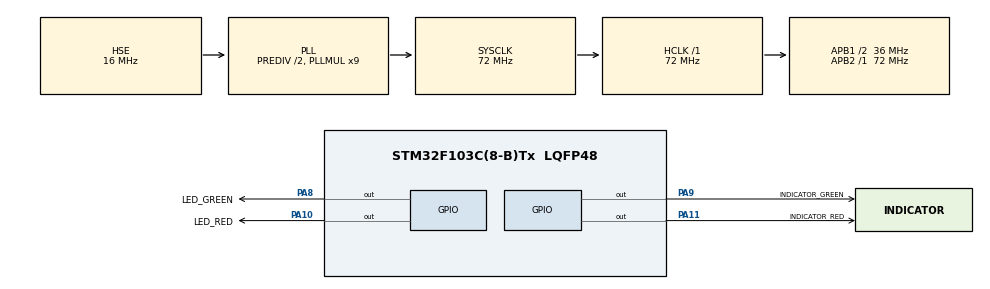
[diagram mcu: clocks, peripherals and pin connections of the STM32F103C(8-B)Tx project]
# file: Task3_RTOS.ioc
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FREERTOS.Tasks01=defaultTask,24,128,StartDefaultTask,Default,NULL,Dynamic,NULL,NULL;LedGreenTask,24,128,LedGreen,Default,NULL,Dynamic,NULL,NULL;LedRedTask,40,128,LedRed,Default,NULL,Dynamic,NULL,NULL
FREERTOS.configUSE_NEWLIB_REENTRANT=1
Mcu.Family=STM32F1
Mcu.Name=STM32F103C(8-B)Tx
Mcu.Package=LQFP48
NVIC.PriorityGroup=NVIC_PRIORITYGROUP_4
NVIC.TIM4_IRQn=true\:15\:0\:false\:false\:true\:false\:false\:true\:true
NVIC.TimeBase=TIM4_IRQn
NVIC.TimeBaseIP=TIM4
PA10.GPIO_Label=LED_RED
PA10.Signal=GPIO_Output
PA11.GPIO_Label=INDICATOR_RED
PA11.Signal=GPIO_Output
PA13.Mode=Serial_Wire
PA13.Signal=SYS_JTMS-SWDIO
PA14.Mode=Serial_Wire
PA14.Signal=SYS_JTCK-SWCLK
PA8.GPIO_Label=LED_GREEN
PA8.Signal=GPIO_Output
PA9.GPIO_Label=INDICATOR_GREEN
PA9.Signal=GPIO_Output
PD0-OSC_IN.Mode=HSE-External-Oscillator
PD0-OSC_IN.Signal=RCC_OSC_IN
PD1-OSC_OUT.Mode=HSE-External-Oscillator
PD1-OSC_OUT.Signal=RCC_OSC_OUT
ProjectManager.HeapSize=0x200
ProjectManager.StackSize=0x400
ProjectManager.TargetToolchain=STM32CubeIDE
RCC.AHBFreq_Value=72000000
RCC.APB1CLKDivider=RCC_HCLK_DIV2
RCC.APB1Freq_Value=36000000
RCC.APB1TimFreq_Value=72000000
RCC.APB2Freq_Value=72000000
RCC.APB2TimFreq_Value=72000000
RCC.HCLKFreq_Value=72000000
RCC.HSEDivPLL=RCC_HSE_PREDIV_DIV2
RCC.HSE_VALUE=16000000
RCC.PLLMUL=RCC_PLL_MUL9
RCC.PLLSourceVirtual=RCC_PLLSOURCE_HSE
RCC.SYSCLKFreq_VALUE=72000000
RCC.SYSCLKSource=RCC_SYSCLKSOURCE_PLLCLK
RCC.USBFreq_Value=72000000
VP_FREERTOS_VS_CMSIS_V2.Mode=CMSIS_V2
VP_SYS_VS_tim4.Mode=TIM4
board=custom

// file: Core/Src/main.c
/* USER CODE BEGIN Header */
/**
  ******************************************************************************
  * @file           : main.c
  * @brief          : Main program body
  ******************************************************************************
  * @attention
  *
  * Copyright (c) 2024 STMicroelectronics.
  * All rights reserved.
  *
  * This software is licensed under terms that can be found in the LICENSE file
  * in the root directory of this software component.
  * If no LICENSE file comes with this software, it is provided AS-IS.
  *
  ******************************************************************************
  */
/* USER CODE END Header */
#include "main.h"
#include "cmsis_os.h"

/* Definitions for defaultTask */
osThreadId_t defaultTaskHandle;
const osThreadAttr_t defaultTask_attributes = {
  .name = "defaultTask",
  .stack_size = 128 * 4,
  .priority = (osPriority_t) osPriorityNormal,
};
/* Definitions for LedGreenTask */
osThreadId_t LedGreenTaskHandle;
const osThreadAttr_t LedGreenTask_attributes = {
  .name = "LedGreenTask",
  .stack_size = 128 * 4,
  .priority = (osPriority_t) osPriorityNormal,
};
/* Definitions for LedRedTask */
osThreadId_t LedRedTaskHandle;
const osThreadAttr_t LedRedTask_attributes = {
  .name = "LedRedTask",
  .stack_size = 128 * 4,
  .priority = (osPriority_t) osPriorityHigh,
};

void SystemClock_Config(void);
static void MX_GPIO_Init(void);
void StartDefaultTask(void *argument);
void LedGreen(void *argument);
void LedRed(void *argument);

int main(void)
{

  /* MCU Configuration--------------------------------------------------------*/

  /* Reset of all peripherals, Initializes the Flash interface and the Systick. */
  HAL_Init();

  /* Configure the system clock */
  SystemClock_Config();

  /* Initialize all configured peripherals */
  MX_GPIO_Init();

  /* Init scheduler */
  osKernelInitialize();

  /* Create the thread(s) */
  /* creation of defaultTask */
  defaultTaskHandle = osThreadNew(StartDefaultTask, NULL, &defaultTask_attributes);

  /* creation of LedGreenTask */
  LedGreenTaskHandle = osThreadNew(LedGreen, NULL, &LedGreenTask_attributes);

  /* creation of LedRedTask */
  LedRedTaskHandle = osThreadNew(LedRed, NULL, &LedRedTask_attributes);

  /* Start scheduler */
  osKernelStart();

  /* We should never get here as control is now taken by the scheduler */

  /* Infinite loop */
  while (1)
  {

  }
}

void SystemClock_Config(void)
{
  RCC_OscInitTypeDef RCC_OscInitStruct = {0};
  RCC_ClkInitTypeDef RCC_ClkInitStruct = {0};

  /** Initializes the RCC Oscillators according to the specified parameters
  * in the RCC_OscInitTypeDef structure.
  */
  RCC_OscInitStruct.OscillatorType = RCC_OSCILLATORTYPE_HSE;
  RCC_OscInitStruct.HSEState = RCC_HSE_ON;
  RCC_OscInitStruct.HSEPredivValue = RCC_HSE_PREDIV_DIV2;
  RCC_OscInitStruct.HSIState = RCC_HSI_ON;
  RCC_OscInitStruct.PLL.PLLState = RCC_PLL_ON;
  RCC_OscInitStruct.PLL.PLLSource = RCC_PLLSOURCE_HSE;
  RCC_OscInitStruct.PLL.PLLMUL = RCC_PLL_MUL9;
  if (HAL_RCC_OscConfig(&RCC_OscInitStruct) != HAL_OK)
  {
    Error_Handler();
  }

  /** Initializes the CPU, AHB and APB buses clocks
  */
  RCC_ClkInitStruct.ClockType = RCC_CLOCKTYPE_HCLK|RCC_CLOCKTYPE_SYSCLK
                              |RCC_CLOCKTYPE_PCLK1|RCC_CLOCKTYPE_PCLK2;
  RCC_ClkInitStruct.SYSCLKSource = RCC_SYSCLKSOURCE_PLLCLK;
  RCC_ClkInitStruct.AHBCLKDivider = RCC_SYSCLK_DIV1;
  RCC_ClkInitStruct.APB1CLKDivider = RCC_HCLK_DIV2;
  RCC_ClkInitStruct.APB2CLKDivider = RCC_HCLK_DIV1;

  if (HAL_RCC_ClockConfig(&RCC_ClkInitStruct, FLASH_LATENCY_2) != HAL_OK)
  {
    Error_Handler();
  }
}

static void MX_GPIO_Init(void)
{
  GPIO_InitTypeDef GPIO_InitStruct = {0};

  /* GPIO Ports Clock Enable */
  __HAL_RCC_GPIOD_CLK_ENABLE();
  __HAL_RCC_GPIOA_CLK_ENABLE();

  /*Configure GPIO pin Output Level */
  HAL_GPIO_WritePin(GPIOA, LED_GREEN_Pin|INDICATOR_GREEN_Pin|LED_RED_Pin|INDICATOR_RED_Pin, GPIO_PIN_RESET);

  /*Configure GPIO pins : LED_GREEN_Pin INDICATOR_GREEN_Pin LED_RED_Pin INDICATOR_RED_Pin */
  GPIO_InitStruct.Pin = LED_GREEN_Pin|INDICATOR_GREEN_Pin|LED_RED_Pin|INDICATOR_RED_Pin;
  GPIO_InitStruct.Mode = GPIO_MODE_OUTPUT_PP;
  GPIO_InitStruct.Pull = GPIO_NOPULL;
  GPIO_InitStruct.Speed = GPIO_SPEED_FREQ_LOW;
  HAL_GPIO_Init(GPIOA, &GPIO_InitStruct);

}

void StartDefaultTask(void *argument)
{
  for(;;)
  {
    osDelay(1);
  }
}

void LedGreen(void *argument)
{
  /* USER CODE BEGIN LedGreen */
  for(;;)
  {
    // 1. Turn the Blue LED on
    HAL_GPIO_WritePin(INDICATOR_GREEN_GPIO_Port, INDICATOR_GREEN_Pin, GPIO_PIN_SET);

    // 2. Simulate task execution - toggle the Green LED for four seconds (toggling rate: 20 Hz)
    for (int i = 0; i < 80; i++) // 4 seconds * 20 Hz = 80 toggles
    {
      HAL_GPIO_TogglePin(LED_GREEN_GPIO_Port, LED_GREEN_Pin);
      HAL_Delay(50); // 50 ms delay for 20 Hz toggling
    }

    // 3. Turn the Green LED off
    HAL_GPIO_WritePin(LED_GREEN_GPIO_Port,LED_GREEN_Pin, GPIO_PIN_RESET);

    // 4. Turn the Blue LED off
    HAL_GPIO_WritePin(INDICATOR_GREEN_GPIO_Port, INDICATOR_GREEN_Pin, GPIO_PIN_RESET);

    // 5. Suspend for six seconds
    osDelay(6000); // delay 6 seconds
  }
  /* USER CODE END LedGreen */
}
void LedRed(void *argument)
{
  /* USER CODE BEGIN LedRed */
  for(;;)
  {
    // 1. Turn the Orange LED on
    HAL_GPIO_WritePin(INDICATOR_RED_GPIO_Port, INDICATOR_RED_Pin, GPIO_PIN_SET);

    // 2. Simulate task execution - toggle the Red LED for 0.5 seconds (toggling rate: 20 Hz)
    for (int i = 0; i < 10; i++) // 0.5 seconds * 20 Hz = 10 toggles
    {
      HAL_GPIO_TogglePin(LED_RED_GPIO_Port, LED_RED_Pin);
      HAL_Delay(50); // 50 ms delay for 20 Hz toggling
    }

    // 3. Turn the Red LED off
    HAL_GPIO_WritePin(LED_RED_GPIO_Port, LED_RED_Pin, GPIO_PIN_RESET);

    // 4. Turn the Orange LED off
    HAL_GPIO_WritePin(INDICATOR_RED_GPIO_Port, INDICATOR_RED_Pin, GPIO_PIN_RESET);

    // 5. Suspend for 1.5 seconds
    osDelay(1500); // delay 1.5 seconds
  }
  /* USER CODE END LedRed */
}

void HAL_TIM_PeriodElapsedCallback(TIM_HandleTypeDef *htim)
{
  if (htim->Instance == TIM4) {
    HAL_IncTick();
  }
}

void Error_Handler(void)
{
  __disable_irq();
  while (1)
  {
  }
}
